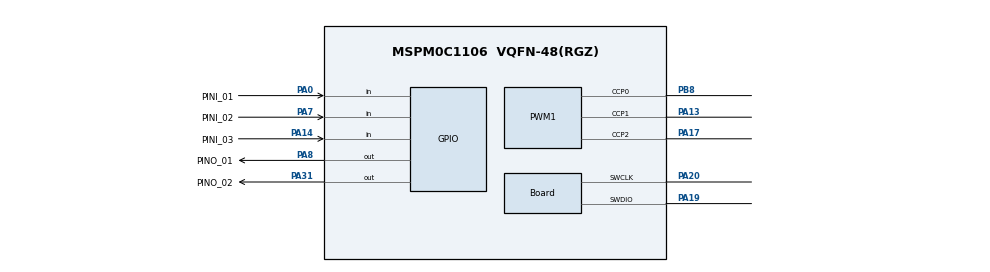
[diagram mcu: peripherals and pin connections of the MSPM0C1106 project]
//@cliArgs --device "MSPM0C1105_C1106" --package "VQFN-48(RGZ)" --part "Default"
//@v2CliArgs --device "MSPM0C1106" --package "VQFN-48(RGZ)"
// @cliArgs --board /ti/boards/LP_MSPM0C1106 --rtos nortos

/**
 * Import the modules used in this configuration.
 */
const ADC12         = scripting.addModule("/ti/driverlib/ADC12", {}, false);
const ADC121        = ADC12.addInstance();
const CAPTURE       = scripting.addModule("/ti/driverlib/CAPTURE", {}, false);
const CAPTURE1      = CAPTURE.addInstance();
const GPIO          = scripting.addModule("/ti/driverlib/GPIO", {}, false);
const GPIO1         = GPIO.addInstance();
const GPIO2         = GPIO.addInstance();
const PWM           = scripting.addModule("/ti/driverlib/PWM", {}, false);
const PWM1          = PWM.addInstance();
const SYSCTL        = scripting.addModule("/ti/driverlib/SYSCTL");
const TIMERFault    = scripting.addModule("/ti/driverlib/TIMERFault", {}, false);
const TIMERFault1   = TIMERFault.addInstance();
const VREF          = scripting.addModule("/ti/driverlib/VREF");
const ProjectConfig = scripting.addModule("/ti/project_config/ProjectConfig");

/**
 * Write custom configuration values to the imported modules.
 */
ADC121.samplingOperationMode       = "sequence";
ADC121.repeatMode                  = true;
ADC121.trigSrc                     = "DL_ADC12_TRIG_SRC_EVENT";
ADC121.sampleTime0                 = "1us";
ADC121.sampleTime1                 = "1us";
ADC121.$name                       = "GEN_ADC_CHAN_0";
ADC121.adcMem0trig                 = "DL_ADC12_TRIGGER_MODE_TRIGGER_NEXT";
ADC121.adcMem2chansel              = "DL_ADC12_INPUT_CHAN_4";
ADC121.adcMem3chansel              = "DL_ADC12_INPUT_CHAN_7";
ADC121.subChanID                   = 1;
ADC121.endAdd                      = 1;
ADC121.adcMem0chansel              = "DL_ADC12_INPUT_CHAN_11";
ADC121.adcMem1chansel              = "DL_ADC12_INPUT_CHAN_9";
ADC121.enabledInterrupts           = ["DL_ADC12_INTERRUPT_MEM1_RESULT_LOADED"];
ADC121.resolution                  = "DL_ADC12_SAMP_CONV_RES_12_BIT";
ADC121.powerDownMode               = "DL_ADC12_POWER_DOWN_MODE_MANUAL";
ADC121.peripheral.$assign          = "ADC0";
ADC121.peripheral.adcPin11.$assign = "PB17";
ADC121.peripheral.adcPin9.$assign  = "PB19";

const Board                       = scripting.addModule("/ti/driverlib/Board", {}, false);
Board.peripheral.$assign          = "DEBUGSS";
Board.peripheral.swclkPin.$assign = "PA20";
Board.peripheral.swdioPin.$assign = "PA19";

CAPTURE1.$name              = "CAPTURE_0";
CAPTURE1.interrupts         = ["CC0_DN"];
CAPTURE1.subscriberPort     = "FSUB0";
CAPTURE1.captSelect         = "Trigger";
CAPTURE1.subscriberChannel  = 2;
CAPTURE1.timerStartTimer    = true;
CAPTURE1.timerPeriod        = "0.5";
CAPTURE1.timerClkDiv        = 8;
CAPTURE1.timerClkPrescale   = 40;
CAPTURE1.peripheral.$assign = "TIMG1";

GPIO1.$name                         = "GEN_GPIO_OUT";
GPIO1.associatedPins.create(2);
GPIO1.associatedPins[0].$name       = "PINO_01";
GPIO1.associatedPins[0].pin.$assign = "PA8";
GPIO1.associatedPins[1].$name       = "PINO_02";
GPIO1.associatedPins[1].pin.$assign = "PA31";

GPIO2.$name                         = "GEN_GPIO_IN";
GPIO2.associatedPins.create(3);
GPIO2.associatedPins[0].$name       = "PINI_01";
GPIO2.associatedPins[0].direction   = "INPUT";
GPIO2.associatedPins[0].interruptEn = true;
GPIO2.associatedPins[0].polarity    = "RISE_FALL";
GPIO2.associatedPins[0].pubChanID   = 2;
GPIO2.associatedPins[0].pin.$assign = "PA0";
GPIO2.associatedPins[1].$name       = "PINI_02";
GPIO2.associatedPins[1].direction   = "INPUT";
GPIO2.associatedPins[1].polarity    = "RISE_FALL";
GPIO2.associatedPins[1].interruptEn = true;
GPIO2.associatedPins[1].pin.$assign = "PA7";
GPIO2.associatedPins[2].$name       = "PINI_03";
GPIO2.associatedPins[2].direction   = "INPUT";
GPIO2.associatedPins[2].polarity    = "RISE_FALL";
GPIO2.associatedPins[2].interruptEn = true;
GPIO2.associatedPins[2].pin.$assign = "PA14";

PWM1.$name                           = "PWM_0";
PWM1.dbFallDelayTimerCount           = 80;
PWM1.dbRiseDelayTimerCount           = 80;
PWM1.timerStartTimer                 = true;
PWM1.pwmMode                         = "CENTER_ALIGN";
PWM1.deadBandEn                      = true;
PWM1.event1PublisherChannel          = 1;
PWM1.event2PublisherChannel          = 2;
PWM1.faultHandlerEn                  = true;
PWM1.faultInput                      = "FI_DEPENDENT";
PWM1.faultInputEn                    = "FIEN_ENABLED";
PWM1.faultInputFilterEn              = true;
PWM1.faultInputDetect                = true;
PWM1.faultChannel0BehaviorEntry      = "LOW";
PWM1.faultChannel0BehaviorExit       = "LOW";
PWM1.faultChannel1BehaviorEntry      = "LOW";
PWM1.faultChannel1BehaviorExit       = "LOW";
PWM1.faultChannel2BehaviorEntry      = "LOW";
PWM1.faultChannel2BehaviorExit       = "LOW";
PWM1.faultSource                     = ["1"];
PWM1.faultConditionDuration          = "FL_LATCH_SW_CLR";
PWM1.faultFilterSamplePeriod         = "8";
PWM1.interrupts                      = ["ZERO_EVENT"];
PWM1.faultChannel3BehaviorEntry      = "LOW";
PWM1.faultChannel3BehaviorExit       = "LOW";
PWM1.timerCount                      = 4000;
PWM1.faultTimerCountEntry            = "FAULT_ENTRY_CTR_SUSP_COUNT";
PWM1.faultTimerCountExit             = "FAULT_EXIT_CTR_CVAE_ACTION";
PWM1.event1ControllerInterruptEn     = ["LOAD_EVENT"];
PWM1.event2ControllerInterruptEn     = ["LOAD_EVENT"];
PWM1.ccIndex                         = [0,1,2];
PWM1.ccIndexCmpl                     = [0,1,2];
PWM1.peripheral.$assign              = "TIMA0";
PWM1.peripheral.ccp0Pin.$assign      = "PB8";
PWM1.peripheral.ccp1Pin.$assign      = "PA13";
PWM1.peripheral.ccp2Pin.$assign      = "PA17";
PWM1.peripheral.ccp0Pin_cmpl.$assign = "PB9";
PWM1.peripheral.ccp1Pin_cmpl.$assign = "PA10";
PWM1.peripheral.ccp2Pin_cmpl.$assign = "PA11";
PWM1.PWM_CHANNEL_0.$name             = "ti_driverlib_pwm_PWMTimerCC1";
PWM1.PWM_CHANNEL_1.$name             = "ti_driverlib_pwm_PWMTimerCC2";
PWM1.PWM_CHANNEL_2.$name             = "ti_driverlib_pwm_PWMTimerCC0";
PWM1.PWM_CHANNEL_2.dutyCycle         = 50;

SYSCTL.validateClkStatus  = true;
SYSCTL.peripheral.$assign = "SYSCTL";

PWM1.associatedFault                             = TIMERFault1;
TIMERFault1.enabledFaults                        = ["1"];
TIMERFault1.$name                                = "FAULT_1";
TIMERFault1.faultPin1.$assign                    = "PA9";

VREF.basicIntVolt       = "DL_VREF_BUFCONFIG_OUTPUT_2_5V";
VREF.peripheral.$assign = "VREF";

ProjectConfig.genDisable         = true;
ProjectConfig.migrationCondition = true;
